# DISPC_COMMON register map
Vendor: Texas Instruments
Peripheral module from a debugger description file (folder TDA3x).
Registers are 32-bit, access per field, reset 0x0 unless marked. A register's access mark holds for its fields unless they carry their own. Offsets are as the file gives them; lines under a group give offsets from that group; [hi:lo] are bit positions; {n}, {i} and the like mark numbered series; 'fields as' and 'values as' point back to an identical list; <NAME> marks a mode.

## DISPC_COMMON
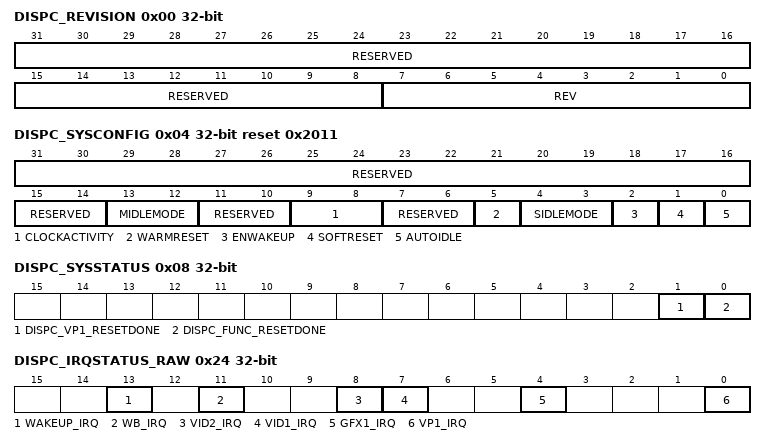
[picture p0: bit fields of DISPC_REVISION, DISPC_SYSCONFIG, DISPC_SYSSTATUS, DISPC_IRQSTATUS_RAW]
0x00 DISPC_REVISION ro (reset mask 0xFFFFFF00) — This register contains the IP revision code
  [31:8] RESERVED — Write 0's for future compatibility. Reads return 0
  [7:0] REV — IP revision
0x04 DISPC_SYSCONFIG reset 0x2011 — This register allows to control various parameters of the OCP interface.
  [31:14] RESERVED ro — Write 0's for future compatibility. Reads returns 0
  [13:12] MIDLEMODE rw — Master interface power management, standby/wait control
    0=FSTANDBY (Force-standby.MStandby is only asserted when the module is disabled. MStandby is only asserted when the module is disabled.); 1=NSTANDBY (No-Standby:MStandby is never asserted); 2=SSTANDBY (Smart-Standby.MStandby is asserted based on the internal activity of the module)
  [11:10] RESERVED ro — Write 0's for future compatibility. Reads returns 0
  [9:8] CLOCKACTIVITY rw — Clocks activity during wake up mode period
    0=OCPFUNCOFF (OCP and Functional clocks can be switched off); 1=FUNCOFF (Functional clocks can be switched off and OCP clocks are mantained during wake up period); 3=OCPFUNCON (OCP and Functional clocks are maintained during wake up period); 2=OCPOFF (OCP clocks can be switched off and Functional clocks are maintained during wake up period)
  [7:6] RESERVED ro — Write 0's for future compatibility. Reads returns 0
  [5] WARMRESET rw — Warm reset. Set this bit to 1 triggers a module warm reset. The bit is automatically reset by the hardware. During reads, it always returns 0. The warm reset keep the configuration registers unchanged.
    0=NORMAL (Normal mode); 1=WARMRESET (the warmreset is set)
  [4:3] SIDLEMODE rw — Slave interface power management, Idle req/ack control
    0=FIDLE (Force-idle.An idle request is acknowledged unconditionally); 1=NIDLE (No-idle. An idle request is never acknowledged); 2=SIDLE (Smart-idle. Acknowledgement to an idle request is given based on the internal activity of the module.)
  [2] ENWAKEUP rw — WakeUp feature control
    0=WAKEUPDIS (Wakeup is disabled); 1=WAKEUPENB (Wakeup is enabled)
  [1] SOFTRESET rw — Software reset. Set this bit to 1 to trigger a module reset. The bit is automatically reset by the hardware. During reads, it always returns 0.
    0=NMODE (Normal mode); 1=RST (The module is reset)
  [0] AUTOIDLE rw — Internal OCP clock gating strategy
    0=CLKFREE (OCP clock is free-running); 1=CLKGATED (Automatic OCP L3 and L4 clocks gating strategy is applied, based on the OCP interface activity.. Automatic functional clock gating is also applied to the functional clock based on the module activity (for instance DISPC_ pipe _ATTRIBUTES.ENABLE))
0x08 DISPC_SYSSTATUS ro — This register provides status information about the module, excluding the interrupt status information.
  [1] DISPC_VP1_RESETDONE — Reset status of DISPC VP1 pixel clock domain
    0=RSTONGOING (Internal module reset is on-going); 1=RSTCOMP (Reset completed)
  [0] DISPC_FUNC_RESETDONE — Reset status of DISPC Functional clock domain
    values as DISPC_VP1_RESETDONE
0x20 DISPC_IRQ_EOI — End Of Interrupt number (for H08 interrupt)
  [0] LINE_NUMBER rw — Software End Of Interrupt (EOI) control. Write number of interrupt output. The IP has 1 interrupt compliant with H08.
    0=READ0 (Reads always 0 (no EOI memory))
0x24 DISPC_IRQSTATUS_RAW — Per-end of group (31 down to 0) internal signaling raw interrupt status vector, line #0. Raw status is set even if end of group (31 down to 0) interrupt is not enabled. Write 1 to set the (raw) status, mostly for debug.
  [all] fields
    0=NONE (No event pending); 1=PENDING (IRQ event pending)
  [13] WAKEUP_IRQ rw — Wake-up
  [11] WB_IRQ rw — WB IRQ STATUS register indicates the write-back pipeline interrupt events
  [8] VID2_IRQ rw — VID2 IRQ STATUS register indicates the video pipeline 2 interrupt events
  [7] VID1_IRQ rw — VID1 IRQ STATUS register indicates the video pipeline 1 interrupt events
  [4] GFX1_IRQ rw — GFX1 IRQ STATUS register indicates the graphics pipeline 1 interrupt events
  [0] VP1_IRQ rw — VP1 IRQ STATUS register indicates the Video Port 1 interrupt events
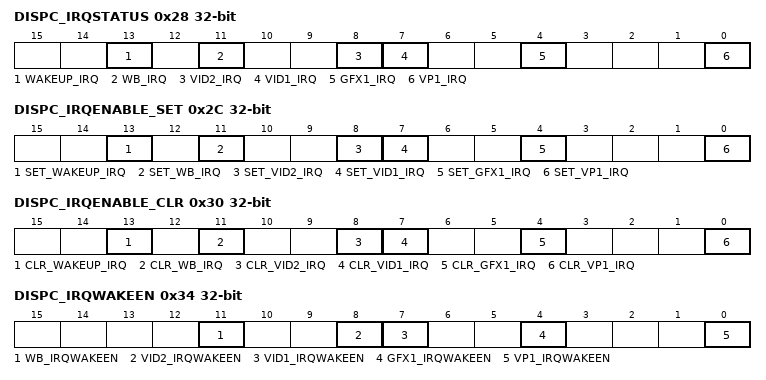
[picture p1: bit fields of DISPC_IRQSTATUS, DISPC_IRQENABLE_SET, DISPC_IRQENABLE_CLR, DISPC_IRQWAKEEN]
0x28 DISPC_IRQSTATUS — Per-end of group (31 down to 0) internal signaling 'enabled' interrupt status vector, line #0. Enabled status isn't set unless event is enabled. Write 1 to clear the status after interrupt has been serviced (raw status gets cleared, i.e. even if not enabled).
  fields as DISPC_IRQSTATUS_RAW
0x2C DISPC_IRQENABLE_SET — Per-end of group (31 down to 0) internal event interrupt enable bit vector, line #0. Write 1 to set (enable interrupt). Readout equal to corresponding _CLR register.
  [all] fields
    0=DISABLED (interrupt disabled); 1=ENABLED (interrupt enabled)
  [13] SET_WAKEUP_IRQ rw — Wake Up Mask
  [11] SET_WB_IRQ rw — WB IRQ
  [8] SET_VID2_IRQ rw — VID2 IRQ
  [7] SET_VID1_IRQ rw — VID1 IRQ
  [4] SET_GFX1_IRQ rw — GFX1 IRQ
  [0] SET_VP1_IRQ rw — VP1 IRQ
0x30 DISPC_IRQENABLE_CLR
  [all] fields
    values as the fields of DISPC_IRQENABLE_SET
  [13] CLR_WAKEUP_IRQ rw — Wake Up Mask
  [11] CLR_WB_IRQ rw — WB IRQ
  [8] CLR_VID2_IRQ rw — VID2 IRQ
  [7] CLR_VID1_IRQ rw — VID1 IRQ
  [4] CLR_GFX1_IRQ rw — GFX1 IRQ
  [0] CLR_VP1_IRQ rw — VP1 IRQ
0x34 DISPC_IRQWAKEEN — IRQ wake up register
  [all] fields
    0=SWAKEUPDIS (Swakeup is not generated when this interrupt is asserted in idle mode); 1=SWAKEUPEN (Swakeup is generated when this interrupt is asserted in idle mode)
  [11] WB_IRQWAKEEN rw — wakeupen for WB first level interrupt
  [8] VID2_IRQWAKEEN rw — wakeupen for VID2 first level interrupt
  [7] VID1_IRQWAKEEN rw — wakeupen for VID1 first level interrupt
  [4] GFX1_IRQWAKEEN rw — wakeupen for GFX1 first level interrupt
  [0] VP1_IRQWAKEEN rw — wakeupen for VP1 first level interrupt
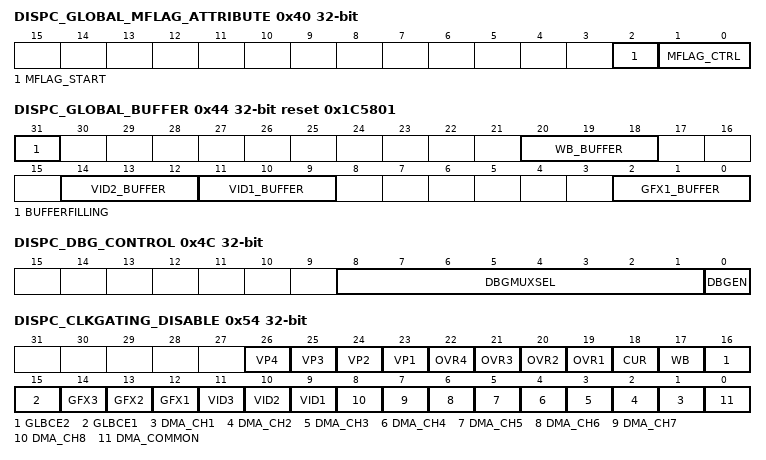
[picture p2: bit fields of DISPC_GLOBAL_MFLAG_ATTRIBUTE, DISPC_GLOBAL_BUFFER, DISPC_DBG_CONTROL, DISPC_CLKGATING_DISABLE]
0x40 DISPC_GLOBAL_MFLAG_ATTRIBUTE — MFLAG control register
  [2] MFLAG_START rw
    0=MFLAGNORMALSTARTMODE (reset value, when the DMA buffer is empty at the beginning of the frame, the MFLAG of each pipe is kept at 0 until PRELOAD is reached, then based on MFLAG_CTRL, MFLAG[1:0] are generated and internal logic is arbitrating between pipeline requests); 1=MFLAGFORCESTARTMODE (Even at the beginning of the frame when the DMA buffer is empty, MFLAG_CTRL is used to determine how MFLAG dedicated to each pipe signal shall be driven)
  [1:0] MFLAG_CTRL rw
    0=MFLAGDIS (MFLAG mechanism is disabled: MFLAG[1:0] out band signals are set to 0); 1=MFLAGFORCE (MFLAG mechanism is enabled: MFLAG[1:0] out band signals are always set to 1); 2=MFLAGEN (MFLAG mechanism is enabled and MFLAG[1:0] out band signals are dynamically set to 0 or 1 depending on the MFLAG rules)
0x44 DISPC_GLOBAL_BUFFER reset 0x1C5801 — The register configures the DMA buffers allocations to the pipeline.
  [31] BUFFERFILLING rw — Controls if the DMA buffers are re-filled only when the LOW threshold is reached or if all DMA buffers are re-filled when at least one of them reaches the LOW threshold. wr: immediate
    0=INDIVIDUALPIPE (Each DMA buffer is re-filled when it reaches LOW threshold.); 1=ALLPIPES (All DMA buffers are re-filled up to high threshold when at least one of them reaches the LOW threshold. (only active DMA buffers shall be considered and when reaching the end of the frame the DMA buffer goes to empty condition so no need to fill it again).)
  [20:18] WB_BUFFER rw — WB DMA buffer allocation to one of the pipelines. By default to video 1 pipeline.
    6=VID3 (DMA buffer allocated to the vdieo3 pipeline.); 1=GFX1 (DMA buffer allocated to the gfx1 pipeline.); 7=WB (DMA buffer allocated to the write-back pipeline.); 0=UNUSED (DMA buffer is not allocated to a pipeline.); 2=GFX2 (DMA buffer allocated to the gfx2 pipeline.); 4=VID1 (DMA buffer allocated to the video1 pipeline.); 5=VID2 (DMA buffer allocated to the vdieo2 pipeline.); 3=GFX3 (DMA buffer allocated to the gfx3 pipeline.)
  [14:12] VID2_BUFFER rw — Video2 DMA buffer allocation to one of the pipelines. By default to video 2 pipeline.
    values as WB_BUFFER
  [11:9] VID1_BUFFER rw — Video1 DMA buffer allocation to one of the pipelines. By default to video 1 pipeline.
    values as WB_BUFFER
  [2:0] GFX1_BUFFER rw — Gfx1 DMA buffer allocation to one of the pipelines. By default to gfx1 pipeline.
    values as WB_BUFFER
0x48 DISPC_BA0_FLIPIMMEDIATE_EN ro — Note: Register is not supported in this family of devices.
0x4C DISPC_DBG_CONTROL — DISPC debug bus control register Note: GFX2, GFX3, VID-3, OVR3, OVR4, VP2, VP3, VP4, GLBCE1 and GLBCE2 are not supported in this family of devices.
  [8:1] DBGMUXSEL rw
    13=VID2SEL5 (Select first [191:160] bits of VID-2 debug bus); 9=VID2SEL1 (Select first [63:32] bits of VID-2 debug bus); 21=VID3SEL5 (Select first [191:160] bits of VID-3 debug bus); 30=GFX2SEL (Select GFX2 debug bus); 8=VID2SEL0 (Select first [31:0] bits of VID-2 debug bus); 5=VID1SEL5 (Select first [191:160] bits of VID-1 debug bus); {v}=OVR{v-24}SEL (Select OVR{v-24} debug bus) (v=25..28); 2=VID1SEL2 (Select first [95:64] bits of VID-1 debug bus); 4=VID1SEL4 (Select first [159:128] bits of VID-1 debug bus); {v}=VP{v-31}SEL (Select VP{v-31} debug bus) (v=32..35); 1=VID1SEL1 (Select first [63:32] bits of VID-1 debug bus); 29=GFX1SEL (Select GFX1 debug bus); 36=GLBCE1SEL (Select GLBCE1 debug bus); 0=VID1SEL0 (Select first [31:0] bits of VID-1 debug bus); 11=VID2SEL3 (Select first [127:96] bits of VID-2 debug bus); 23=VID3SEL7 (Select first [255:224] bits of VID-3 debug bus); 17=VID3SEL1 (Select first [63:32] bits of VID-3 debug bus); 6=VID1SEL6 (Select first [223:192] bits of VID-1 debug bus); 10=VID2SEL2 (Select first [95:64] bits of VID-2 debug bus); 16=VID3SEL0 (Select first [31:0] bits of VID-3 debug bus); 37=GLBCE2SEL (Select GLBCE2 debug bus); 18=VID3SEL2 (Select first [95:64] bits of VID-3 debug bus); 19=VID3SEL3 (Select first [127:96] bits of VID-3 debug bus); 24=WBSEL (Select WB debug bus); 20=VID3SEL4 (Select first [159:128] bits of VID-3 debug bus); 14=VID2SEL6 (Select first [223:192] bits of VID-2 debug bus); 22=VID3SEL6 (Select first [223:192] bits of VID-3 debug bus); 7=VID1SEL7 (Select first [255:224] bits of VID-1 debug bus); 3=VID1SEL3 (Select first [127:96] bits of VID-1 debug bus); 31=GFX3SEL (Select GFX3 debug bus); 15=VID2SEL7 (Select first [255:224] bits of VID-2 debug bus); 12=VID2SEL4 (Select first [159:128] bits of VID-2 debug bus)
  [0] DBGEN rw — Enable debug ports
    0=DBGDIS; 1=DBGEN
0x50 DISPC_DBG_STATUS ro — DISPC debug status register
  [31:0] DBGOUT
0x54 DISPC_CLKGATING_DISABLE — Register to control clock gating at DISPC sub-module level Note: CUR, GFX2, GFX3, VID3, OVR3, OVR4, VP2, VP3, VP4, GLBCE1 and GLBCE2 are not supported in this family of devices.
  [all] fields
    0=CLKGATINGEN (Clock-Gating is enabled); 1=CLKGATINGDIS (Clock-gating is disabled. Clocks are free running)
  [n+22] VP{n} rw (n=1..4) — Clock gating control for VP{n}
  [n+18] OVR{n} rw (n=1..4) — Clock gating control for OVR{n}
  [18] CUR rw — Clock gating control for CUR
  [17] WB rw — Clock gating control for WB
  [16] GLBCE2 rw — Clock gating control for GLBCE2
  [15] GLBCE1 rw — Clock gating control for GLBCE1
  [14] GFX3 rw — Clock gating control for GFX3
  [13] GFX2 rw — Clock gating control for GFX2
  [12] GFX1 rw — Clock gating control for GFX1
  [11] VID3 rw — Clock gating control for VID3
  [10] VID2 rw — Clock gating control for VID2
  [9] VID1 rw — Clock gating control for VID1
  [n] DMA_CH{n} rw (n=1..8) — Clock gating control for DMA Channel-{n}
  [0] DMA_COMMON rw — Clock gating control for DMA_COMMON module
